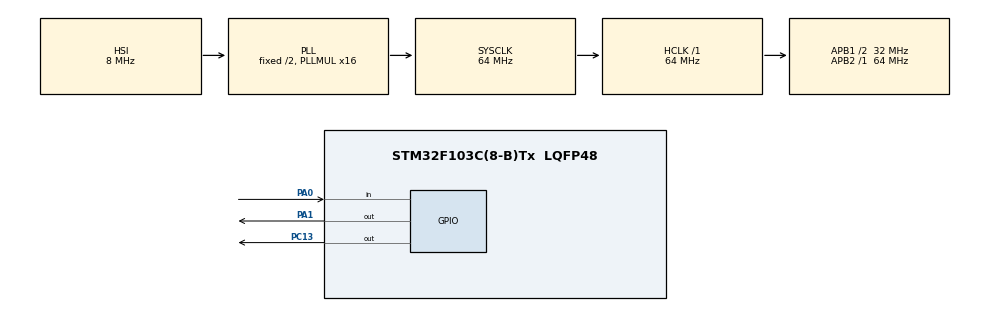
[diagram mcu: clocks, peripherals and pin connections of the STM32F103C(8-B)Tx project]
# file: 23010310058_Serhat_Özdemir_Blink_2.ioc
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Mcu.Family=STM32F1
Mcu.Name=STM32F103C(8-B)Tx
Mcu.Package=LQFP48
NVIC.PriorityGroup=NVIC_PRIORITYGROUP_4
NVIC.TIM2_IRQn=true\:0\:0\:false\:false\:true\:true\:true\:true
PA0-WKUP.Signal=GPIO_Input
PA1.Signal=GPIO_Output
PC13-TAMPER-RTC.Signal=GPIO_Output
ProjectManager.HeapSize=0x200
ProjectManager.StackSize=0x400
ProjectManager.TargetToolchain=STM32CubeIDE
RCC.AHBFreq_Value=64000000
RCC.APB1CLKDivider=RCC_HCLK_DIV2
RCC.APB1Freq_Value=32000000
RCC.APB1TimFreq_Value=64000000
RCC.APB2Freq_Value=64000000
RCC.APB2TimFreq_Value=64000000
RCC.HCLKFreq_Value=64000000
RCC.PLLMUL=RCC_PLL_MUL16
RCC.SYSCLKFreq_VALUE=64000000
RCC.SYSCLKSource=RCC_SYSCLKSOURCE_PLLCLK
RCC.USBFreq_Value=64000000
TIM2.Period=9999
TIM2.Prescaler=6399
VP_SYS_VS_ND.Mode=No_Debug
VP_TIM2_VS_ClockSourceINT.Mode=Internal
board=custom

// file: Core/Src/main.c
/* USER CODE BEGIN Header */
/**
  ******************************************************************************
  * @file           : main.c
  * @brief          : Main program body
  ******************************************************************************
  * @attention
  *
  * Copyright (c) 2026 STMicroelectronics.
  * All rights reserved.
  *
  * This software is licensed under terms that can be found in the LICENSE file
  * in the root directory of this software component.
  * If no LICENSE file comes with this software, it is provided AS-IS.
  *
  ******************************************************************************
  */
/* USER CODE END Header */
#include "main.h"

TIM_HandleTypeDef htim2;

/* USER CODE BEGIN PV */
uint16_t blink_count;
uint32_t flash_addr = 0x0800FC00;
uint8_t toggle_state = 0;
uint16_t current_blink = 0;
uint8_t is_waiting = 0;
uint16_t wait_seconds = 0;
uint32_t button_press_time = 0;
uint8_t button_handled = 0;

/* USER CODE END PV */

void SystemClock_Config(void);
static void MX_GPIO_Init(void);
static void MX_TIM2_Init(void);

/* USER CODE BEGIN 0 */
uint16_t Flash_Read(uint32_t address) {
    return *(__IO uint16_t*)address;
}

void Flash_Write(uint32_t address, uint16_t value) {
    HAL_FLASH_Unlock();
    FLASH_EraseInitTypeDef EraseInitStruct;
    uint32_t PageError;
    EraseInitStruct.TypeErase = FLASH_TYPEERASE_PAGES;
    EraseInitStruct.PageAddress = address;
    EraseInitStruct.NbPages = 1;
    HAL_FLASHEx_Erase(&EraseInitStruct, &PageError);
    HAL_FLASH_Program(FLASH_TYPEPROGRAM_HALFWORD, address, value);
    HAL_FLASH_Lock();
}

void HAL_TIM_PeriodElapsedCallback(TIM_HandleTypeDef *htim) {
    if (htim->Instance == TIM2) {
        if (!is_waiting) {
            HAL_GPIO_TogglePin(GPIOC, GPIO_PIN_13);
            toggle_state++;
            if (toggle_state >= 2) {
                toggle_state = 0;
                current_blink++;
            }
            if (current_blink >= blink_count) {
                is_waiting = 1;
                current_blink = 0;
                HAL_GPIO_WritePin(GPIOC, GPIO_PIN_13, GPIO_PIN_SET); // LED Sönük (Active Low)
            }
        } else {
            wait_seconds++;
            if (wait_seconds >= 5) {
                wait_seconds = 0;
                is_waiting = 0;
            }
        }
    }
}
/* USER CODE END 0 */

int main(void)
{

  /* MCU Configuration--------------------------------------------------------*/

  /* Reset of all peripherals, Initializes the Flash interface and the Systick. */
  HAL_Init();

  /* Configure the system clock */
  SystemClock_Config();

  /* Initialize all configured peripherals */
  MX_GPIO_Init();
  MX_TIM2_Init();
  /* USER CODE BEGIN 2 */
  blink_count = Flash_Read(flash_addr);
  if (blink_count < 4 || blink_count > 7) {
      blink_count = 4;
      Flash_Write(flash_addr, blink_count);
  }
  HAL_TIM_Base_Start_IT(&htim2);

  /* USER CODE END 2 */

  /* Infinite loop */
  /* USER CODE BEGIN WHILE */
  while (1)
  {
	  if (HAL_GPIO_ReadPin(GPIOA, GPIO_PIN_0) == GPIO_PIN_SET) {
	      if (button_press_time == 0) button_press_time = HAL_GetTick();
	      if ((HAL_GetTick() - button_press_time >= 3000) && !button_handled) {
	          blink_count = 4;
	          Flash_Write(flash_addr, blink_count);
	          button_handled = 1;
	      }
	  } else {
	      if (button_press_time != 0) {
	          if (HAL_GetTick() - button_press_time < 3000 && !button_handled) {
	              blink_count++;
	              if (blink_count > 7) blink_count = 4;
	              Flash_Write(flash_addr, blink_count);
	          }
	          button_press_time = 0;
	          button_handled = 0;
	      }
	  }
	  HAL_Delay(10);
    /* USER CODE END WHILE */

  }
}

void SystemClock_Config(void)
{
  RCC_OscInitTypeDef RCC_OscInitStruct = {0};
  RCC_ClkInitTypeDef RCC_ClkInitStruct = {0};

  /** Initializes the RCC Oscillators according to the specified parameters
  * in the RCC_OscInitTypeDef structure.
  */
  RCC_OscInitStruct.OscillatorType = RCC_OSCILLATORTYPE_HSI;
  RCC_OscInitStruct.HSIState = RCC_HSI_ON;
  RCC_OscInitStruct.HSICalibrationValue = RCC_HSICALIBRATION_DEFAULT;
  RCC_OscInitStruct.PLL.PLLState = RCC_PLL_ON;
  RCC_OscInitStruct.PLL.PLLSource = RCC_PLLSOURCE_HSI_DIV2;
  RCC_OscInitStruct.PLL.PLLMUL = RCC_PLL_MUL16;
  if (HAL_RCC_OscConfig(&RCC_OscInitStruct) != HAL_OK)
  {
    Error_Handler();
  }

  /** Initializes the CPU, AHB and APB buses clocks
  */
  RCC_ClkInitStruct.ClockType = RCC_CLOCKTYPE_HCLK|RCC_CLOCKTYPE_SYSCLK
                              |RCC_CLOCKTYPE_PCLK1|RCC_CLOCKTYPE_PCLK2;
  RCC_ClkInitStruct.SYSCLKSource = RCC_SYSCLKSOURCE_PLLCLK;
  RCC_ClkInitStruct.AHBCLKDivider = RCC_SYSCLK_DIV1;
  RCC_ClkInitStruct.APB1CLKDivider = RCC_HCLK_DIV2;
  RCC_ClkInitStruct.APB2CLKDivider = RCC_HCLK_DIV1;

  if (HAL_RCC_ClockConfig(&RCC_ClkInitStruct, FLASH_LATENCY_2) != HAL_OK)
  {
    Error_Handler();
  }
}

static void MX_TIM2_Init(void)
{

  TIM_ClockConfigTypeDef sClockSourceConfig = {0};
  TIM_MasterConfigTypeDef sMasterConfig = {0};

  htim2.Instance = TIM2;
  htim2.Init.Prescaler = 6399;
  htim2.Init.CounterMode = TIM_COUNTERMODE_UP;
  htim2.Init.Period = 9999;
  htim2.Init.ClockDivision = TIM_CLOCKDIVISION_DIV1;
  htim2.Init.AutoReloadPreload = TIM_AUTORELOAD_PRELOAD_DISABLE;
  if (HAL_TIM_Base_Init(&htim2) != HAL_OK)
  {
    Error_Handler();
  }
  sClockSourceConfig.ClockSource = TIM_CLOCKSOURCE_INTERNAL;
  if (HAL_TIM_ConfigClockSource(&htim2, &sClockSourceConfig) != HAL_OK)
  {
    Error_Handler();
  }
  sMasterConfig.MasterOutputTrigger = TIM_TRGO_RESET;
  sMasterConfig.MasterSlaveMode = TIM_MASTERSLAVEMODE_DISABLE;
  if (HAL_TIMEx_MasterConfigSynchronization(&htim2, &sMasterConfig) != HAL_OK)
  {
    Error_Handler();
  }

}

static void MX_GPIO_Init(void)
{
  GPIO_InitTypeDef GPIO_InitStruct = {0};

  /* GPIO Ports Clock Enable */
  __HAL_RCC_GPIOC_CLK_ENABLE();
  __HAL_RCC_GPIOA_CLK_ENABLE();

  /*Configure GPIO pin Output Level */
  HAL_GPIO_WritePin(GPIOC, GPIO_PIN_13, GPIO_PIN_RESET);

  /*Configure GPIO pin Output Level */
  HAL_GPIO_WritePin(GPIOA, GPIO_PIN_1, GPIO_PIN_RESET);

  /*Configure GPIO pin : PC13 */
  GPIO_InitStruct.Pin = GPIO_PIN_13;
  GPIO_InitStruct.Mode = GPIO_MODE_OUTPUT_PP;
  GPIO_InitStruct.Pull = GPIO_NOPULL;
  GPIO_InitStruct.Speed = GPIO_SPEED_FREQ_LOW;
  HAL_GPIO_Init(GPIOC, &GPIO_InitStruct);

  /*Configure GPIO pin : PA0 */
  GPIO_InitStruct.Pin = GPIO_PIN_0;
  GPIO_InitStruct.Mode = GPIO_MODE_INPUT;
  GPIO_InitStruct.Pull = GPIO_NOPULL;
  HAL_GPIO_Init(GPIOA, &GPIO_InitStruct);

  /*Configure GPIO pin : PA1 */
  GPIO_InitStruct.Pin = GPIO_PIN_1;
  GPIO_InitStruct.Mode = GPIO_MODE_OUTPUT_PP;
  GPIO_InitStruct.Pull = GPIO_NOPULL;
  GPIO_InitStruct.Speed = GPIO_SPEED_FREQ_LOW;
  HAL_GPIO_Init(GPIOA, &GPIO_InitStruct);

}

void Error_Handler(void)
{
  __disable_irq();
  while (1)
  {
  }
}
